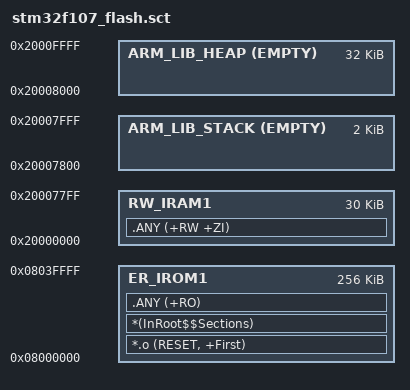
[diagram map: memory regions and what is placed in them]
;********************************************************************
;* STM32F107 linker scatter file (running code from internal FLASH) *
;********************************************************************

LR_IROM1 0x08000000 0x40000
{
   ER_IROM1 0x08000000 0x40000
   {
      *.o (RESET, +First)
      *(InRoot$$Sections)
      .ANY (+RO)
   }
   
   RW_IRAM1 0x20000000 0x7800
   {
      .ANY (+RW +ZI)
   }
   
   ARM_LIB_STACK 0x20008000 EMPTY -0x800
   {
   }
   
   ARM_LIB_HEAP 0x20008000 EMPTY 0x8000
   {
   }
}
